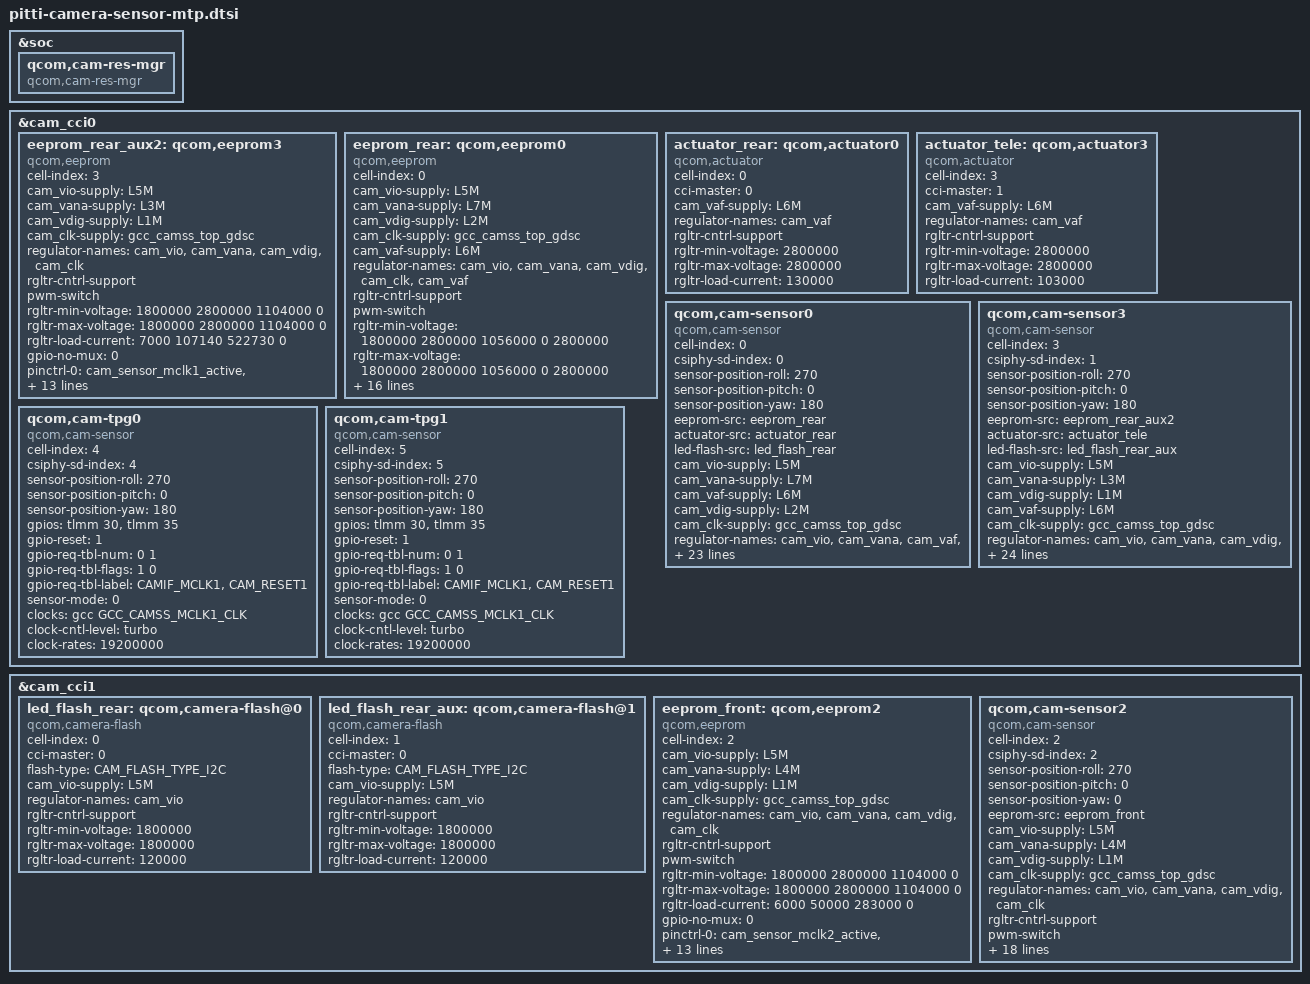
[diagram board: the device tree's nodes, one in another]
#include <dt-bindings/msm-camera.h>
#include <dt-bindings/clock/qcom,gcc-pitti.h>

&soc {
	qcom,cam-res-mgr {
		compatible = "qcom,cam-res-mgr";
		status = "ok";
	};
};

&cam_cci0 {
	eeprom_rear_aux2: qcom,eeprom3 {
		cell-index = <3>;
		compatible = "qcom,eeprom";
		cam_vio-supply = <&L5M>;
		cam_vana-supply = <&L3M>;
		cam_vdig-supply = <&L1M>;
		cam_clk-supply = <&gcc_camss_top_gdsc>;
		regulator-names = "cam_vio", "cam_vana", "cam_vdig",
			"cam_clk";
		rgltr-cntrl-support;
		pwm-switch;
		rgltr-min-voltage = <1800000 2800000 1104000 0>;
		rgltr-max-voltage = <1800000 2800000 1104000 0>;
		rgltr-load-current = <7000 107140 522730 0>;
		gpio-no-mux = <0>;
		pinctrl-names = "cam_default", "cam_suspend";
		pinctrl-0 = <&cam_sensor_mclk1_active
				&cam_sensor_active_rst1>;
		pinctrl-1 = <&cam_sensor_mclk1_suspend
				&cam_sensor_suspend_rst1>;
		gpios = <&tlmm 25 0>,
			<&tlmm 28 0>;
		gpio-reset = <1>;
		gpio-req-tbl-num = <0 1>;
		gpio-req-tbl-flags = <1 0>;
		gpio-req-tbl-label = "CAMIF_MCLK1",
					"CAM_RESET1";
		sensor-mode = <0>;
		cci-master = <1>;
		status = "ok";
		clocks = <&gcc GCC_CAMSS_MCLK1_CLK>;
		clock-names = "cam_clk";
		clock-cntl-level = "turbo";
		clock-rates = <19200000>;
	};

       eeprom_rear: qcom,eeprom0 {
		cell-index = <0>;
		compatible = "qcom,eeprom";
		cam_vio-supply = <&L5M>;
		cam_vana-supply = <&L7M>;
		cam_vdig-supply = <&L2M>;
		cam_clk-supply = <&gcc_camss_top_gdsc>;
		cam_vaf-supply = <&L6M>;
		regulator-names = "cam_vio", "cam_vana", "cam_vdig",
			"cam_clk", "cam_vaf";
		rgltr-cntrl-support;
		pwm-switch;
		rgltr-min-voltage = <1800000 2800000 1056000 0 2800000>;
		rgltr-max-voltage = <1800000 2800000 1056000 0 2800000>;
		rgltr-load-current = <4000 68000 261000 0 130000>;
		gpio-no-mux = <0>;
		pinctrl-names = "cam_default", "cam_suspend";
		pinctrl-0 = <&cam_sensor_mclk0_active
				&cam_sensor_active_rst0>;
		pinctrl-1 = <&cam_sensor_mclk0_suspend
				&cam_sensor_suspend_rst0>;
		gpios = <&tlmm 24 0>,
			<&tlmm 27 0>;
		gpio-reset = <1>;
		gpio-req-tbl-num = <0 1>;
		gpio-req-tbl-flags = <1 0>;
		gpio-req-tbl-label = "CAMIF_MCLK0",
					"CAM_RESET0";
		sensor-mode = <0>;
		cci-master = <0>;
		status = "ok";
		clocks = <&gcc GCC_CAMSS_MCLK0_CLK>;
		clock-names = "cam_clk";
		clock-cntl-level = "turbo";
		clock-rates = <19200000>;
	};

	actuator_rear: qcom,actuator0 {
		cell-index = <0>;
		compatible = "qcom,actuator";
		cci-master = <0>;
		cam_vaf-supply = <&L6M>;
		regulator-names = "cam_vaf";
		rgltr-cntrl-support;
		rgltr-min-voltage = <2800000>;
		rgltr-max-voltage = <2800000>;
		rgltr-load-current = <130000>;
		status = "ok";
	};

	actuator_tele: qcom,actuator3 {
		cell-index = <3>;
		compatible = "qcom,actuator";
		cci-master = <1>;
		cam_vaf-supply = <&L6M>;
		regulator-names = "cam_vaf";
		rgltr-cntrl-support;
		rgltr-min-voltage = <2800000>;
		rgltr-max-voltage = <2800000>;
		rgltr-load-current = <103000>;
		status = "ok";
	};

	/* Rear*/
	qcom,cam-sensor0 {
		cell-index = <0>;
		compatible = "qcom,cam-sensor";
		csiphy-sd-index = <0>;
		sensor-position-roll = <270>;
		sensor-position-pitch = <0>;
		sensor-position-yaw = <180>;
		eeprom-src = <&eeprom_rear>;
		actuator-src = <&actuator_rear>;
		led-flash-src = <&led_flash_rear>;
		cam_vio-supply = <&L5M>;
		cam_vana-supply = <&L7M>;
		cam_vaf-supply = <&L6M>;
		cam_vdig-supply = <&L2M>;
		cam_clk-supply = <&gcc_camss_top_gdsc>;
		regulator-names = "cam_vio", "cam_vana", "cam_vaf", "cam_vdig",
			"cam_clk";
		rgltr-cntrl-support;
		pwm-switch;
		rgltr-min-voltage = <1800000 2800000 2800000 1056000 0>;
		rgltr-max-voltage = <1800000 2800000 2800000 1056000 0>;
		rgltr-load-current = <4000 68000 130000 261000 0>;
		gpio-no-mux = <0>;
		pinctrl-names = "cam_default", "cam_suspend";
		pinctrl-0 = <&cam_sensor_mclk0_active
			&cam_sensor_active_rst0>;
		pinctrl-1 = <&cam_sensor_mclk0_suspend
			&cam_sensor_suspend_rst0>;
		gpios = <&tlmm 24 0>,
		      <&tlmm 27 0>;
		gpio-reset = <1>;
		gpio-req-tbl-num = <0 1>;
		gpio-req-tbl-flags = <1 0>;
		gpio-req-tbl-label = "CAMIF_MCLK0",
			"CAM_RESET0";
		sensor-mode = <0>;
		cci-master = <0>;
		status = "ok";
		clocks = <&gcc GCC_CAMSS_MCLK0_CLK>;
		clock-names = "cam_clk";
		clock-cntl-level = "turbo";
		clock-rates = <19200000>;
	};

	/*Rear Aux2*/
	qcom,cam-sensor3 {
		cell-index = <3>;
		compatible = "qcom,cam-sensor";
		csiphy-sd-index = <1>;
		sensor-position-roll = <270>;
		sensor-position-pitch = <0>;
		sensor-position-yaw = <180>;
		eeprom-src = <&eeprom_rear_aux2>;
		actuator-src = <&actuator_tele>;
		led-flash-src = <&led_flash_rear_aux>;
		cam_vio-supply = <&L5M>;
		cam_vana-supply = <&L3M>;
		cam_vdig-supply = <&L1M>;
		cam_vaf-supply = <&L6M>;
		cam_clk-supply = <&gcc_camss_top_gdsc>;
		regulator-names = "cam_vio", "cam_vana", "cam_vdig",
			"cam_vaf", "cam_clk";
		rgltr-cntrl-support;
		pwm-switch;
		rgltr-min-voltage = <1800000 2800000 1104000 2800000 0>;
		rgltr-max-voltage = <1800000 2800000 1104000 2800000 0>;
		rgltr-load-current = <7000 107140 522730 103000 0>;
		gpio-no-mux = <0>;
		pinctrl-names = "cam_default", "cam_suspend";
		pinctrl-0 = <&cam_sensor_mclk1_active
				&cam_sensor_active_rst1>;
		pinctrl-1 = <&cam_sensor_mclk1_suspend
				&cam_sensor_suspend_rst1>;
		gpios = <&tlmm 25 0>,
			<&tlmm 28 0>;
		gpio-reset = <1>;
		gpio-req-tbl-num = <0 1>;
		gpio-req-tbl-flags = <1 0>;
		gpio-req-tbl-label = "CAMIF_MCLK1",
					"CAM_RESET1";
		sensor-mode = <0>;
		cci-master = <1>;
		status = "ok";
		clocks = <&gcc GCC_CAMSS_MCLK1_CLK>;
		clock-names = "cam_clk";
		clock-cntl-level = "turbo";
		clock-rates = <19200000>;
	};

	/*TPG0*/
	qcom,cam-tpg0 {
		cell-index = <4>;
		compatible = "qcom,cam-sensor";
		csiphy-sd-index = <4>;
		sensor-position-roll = <270>;
		sensor-position-pitch = <0>;
		sensor-position-yaw = <180>;
		gpios = <&tlmm 30 0>,
			<&tlmm 35 0>;
		gpio-reset = <1>;
		gpio-req-tbl-num = <0 1>;
		gpio-req-tbl-flags = <1 0>;
		gpio-req-tbl-label = "CAMIF_MCLK1",
					"CAM_RESET1";
		sensor-mode = <0>;
		status = "ok";
		clocks = <&gcc GCC_CAMSS_MCLK1_CLK>;
		clock-names = "cam_clk";
		clock-cntl-level = "turbo";
		clock-rates = <19200000>;
	};

	/*TPG1*/
	qcom,cam-tpg1 {
		cell-index = <5>;
		compatible = "qcom,cam-sensor";
		csiphy-sd-index = <5>;
		sensor-position-roll = <270>;
		sensor-position-pitch = <0>;
		sensor-position-yaw = <180>;
		gpios = <&tlmm 30 0>,
			<&tlmm 35 0>;
		gpio-reset = <1>;
		gpio-req-tbl-num = <0 1>;
		gpio-req-tbl-flags = <1 0>;
		gpio-req-tbl-label = "CAMIF_MCLK1",
					"CAM_RESET1";
		sensor-mode = <0>;
		status = "ok";
		clocks = <&gcc GCC_CAMSS_MCLK1_CLK>;
		clock-names = "cam_clk";
		clock-cntl-level = "turbo";
		clock-rates = <19200000>;
	};

};

&cam_cci1 {
	led_flash_rear: qcom,camera-flash@0 {
		cell-index = <0>;
		compatible = "qcom,camera-flash";
		cci-master = <0>;
		flash-type = <CAM_FLASH_TYPE_I2C>;
		cam_vio-supply = <&L5M>;
		regulator-names = "cam_vio";
		rgltr-cntrl-support;
		rgltr-min-voltage = <1800000>;
		rgltr-max-voltage = <1800000>;
		rgltr-load-current = <120000>;
		status = "ok";
	};

	led_flash_rear_aux: qcom,camera-flash@1 {
		cell-index = <1>;
		compatible = "qcom,camera-flash";
		cci-master = <0>;
		flash-type = <CAM_FLASH_TYPE_I2C>;
		cam_vio-supply = <&L5M>;
		regulator-names = "cam_vio";
		rgltr-cntrl-support;
		rgltr-min-voltage = <1800000>;
		rgltr-max-voltage = <1800000>;
		rgltr-load-current = <120000>;
		status = "ok";
	};

	eeprom_front: qcom,eeprom2 {
		cell-index = <2>;
		compatible = "qcom,eeprom";
		cam_vio-supply = <&L5M>;
		cam_vana-supply = <&L4M>;
		cam_vdig-supply = <&L1M>;
		cam_clk-supply = <&gcc_camss_top_gdsc>;
		regulator-names = "cam_vio", "cam_vana","cam_vdig",
			"cam_clk";
		rgltr-cntrl-support;
		pwm-switch;
		rgltr-min-voltage = <1800000 2800000 1104000 0>;
		rgltr-max-voltage = <1800000 2800000 1104000 0>;
		rgltr-load-current = <6000 50000 283000 0>;
		gpio-no-mux = <0>;
		pinctrl-names = "cam_default", "cam_suspend";
		pinctrl-0 = <&cam_sensor_mclk2_active
				&cam_sensor_active_rst2>;
		pinctrl-1 = <&cam_sensor_mclk2_suspend
				&cam_sensor_suspend_rst2>;
		gpios = <&tlmm 26 0>,
			<&tlmm 29 0>;
		gpio-reset = <1>;
		gpio-req-tbl-num = <0 1>;
		gpio-req-tbl-flags = <1 0>;
		gpio-req-tbl-label = "CAMIF_MCLK2",
					"CAM_RESET2";
		sensor-mode = <0>;
		cci-master = <0>;
		status = "ok";
		clocks = <&gcc GCC_CAMSS_MCLK2_CLK>;
		clock-names = "cam_clk";
		clock-cntl-level = "turbo";
		clock-rates = <19200000>;
	};

	/*Front OV32C Sensor*/
	qcom,cam-sensor2 {
		cell-index = <2>;
		compatible = "qcom,cam-sensor";
		csiphy-sd-index = <2>;
		sensor-position-roll = <270>;
		sensor-position-pitch = <0>;
		sensor-position-yaw = <0>;
		eeprom-src = <&eeprom_front>;
		cam_vio-supply = <&L5M>;
		cam_vana-supply = <&L4M>;
		cam_vdig-supply = <&L1M>;
		cam_clk-supply = <&gcc_camss_top_gdsc>;
		regulator-names = "cam_vio", "cam_vana","cam_vdig",
			"cam_clk";
		rgltr-cntrl-support;
		pwm-switch;
		rgltr-min-voltage = <1800000 2800000 1104000 0>;
		rgltr-max-voltage = <1800000 2800000 1104000 0>;
		rgltr-load-current = <6000 50000 283000 0>;
		gpio-no-mux = <0>;
		pinctrl-names = "cam_default", "cam_suspend";
		pinctrl-0 = <&cam_sensor_mclk2_active
				&cam_sensor_active_rst2>;
		pinctrl-1 = <&cam_sensor_mclk2_suspend
				&cam_sensor_suspend_rst2>;
		gpios = <&tlmm 26 0>,
			<&tlmm 29 0>;
		gpio-reset = <1>;
		gpio-req-tbl-num = <0 1>;
		gpio-req-tbl-flags = <1 0>;
		gpio-req-tbl-label = "CAMIF_MCLK2",
					"CAM_RESET2";
		sensor-mode = <0>;
		cci-master = <0>;
		status = "ok";
		clocks = <&gcc GCC_CAMSS_MCLK2_CLK>;
		clock-names = "cam_clk";
		clock-cntl-level = "turbo";
		clock-rates = <19200000>;
	};
};
